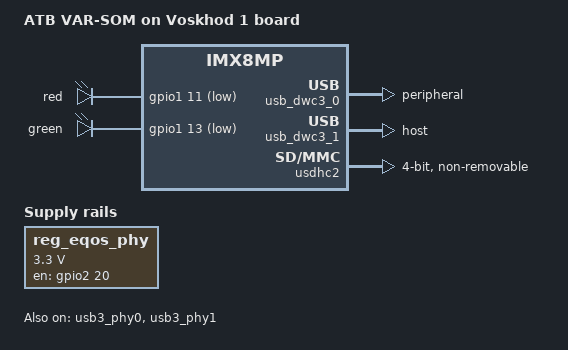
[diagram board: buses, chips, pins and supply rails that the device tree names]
// SPDX-License-Identifier: (GPL-2.0+ OR MIT)
/*
 * Copyright 2019 NXP
 * Copyright 2022 ATB
 */

/dts-v1/;

#include "imx8mp-var-som.dtsi"

/ {
	model = "ATB VAR-SOM on Voskhod 1 board";

	chosen {
		bootargs = "console=ttymxc1,115200 earlycon=ec_imx6q,0x30890000,115200";
		stdout-path = &uart2;
	};
	
	// TODO: Check
	leds {
		compatible = "gpio-leds";
		pinctrl-names = "default";
		pinctrl-0 = <&pinctrl_gpio_led>;

		red {
			label = "red";
			gpios = <&gpio1 11 GPIO_ACTIVE_LOW>;
			linux,default-trigger = "red";
			default-state = "off";
		};

		green {
			label = "green";
			gpios = <&gpio1 13 GPIO_ACTIVE_LOW>;
			linux,default-trigger = "green";
			default-state = "off";
		};
	};
	
	reg_eqos_phy: regulator-eqos-phy {
		compatible = "regulator-fixed";
		regulator-name = "eqos-phy";
		regulator-min-microvolt = <3300000>;
		regulator-max-microvolt = <3300000>;
		gpio = <&gpio2 20 GPIO_ACTIVE_HIGH>;
		enable-active-high;
		regulator-always-on;
	};
};

// TODO: Check
&usb3_phy0 {
	status = "okay";
};
// TODO: Check
&usb_dwc3_0 {
	dr_mode = "peripheral";
//	dr_mode = "otg";
	hnp-disable;
	srp-disable;
	adp-disable;
	usb-role-switch;
	status = "okay";
};
// TODO: Check
&usb3_phy1 {
	status = "okay";
};
// TODO: Check
&usb_dwc3_1 {
	dr_mode = "host";
	status = "okay";
};

// TODO: Check
&usdhc2 {
	pinctrl-names = "default", "state_100mhz", "state_200mhz";
	pinctrl-0 = <&pinctrl_usdhc2>, <&pinctrl_usdhc2_gpio>;
	pinctrl-1 = <&pinctrl_usdhc2_100mhz>, <&pinctrl_usdhc2_gpio>;
	pinctrl-2 = <&pinctrl_usdhc2_200mhz>, <&pinctrl_usdhc2_gpio>;
	// Card detect pin is temporarely unavailable.
	// Non removble mode is used.
//	cd-gpios = <&gpio1 14 GPIO_ACTIVE_LOW>;
	non-removable;
	bus-width = <4>;
	status = "okay";
};

&iomuxc {
	pinctrl_gpio_led: gpioledgrp {
		fsl,pins = <
			MX8MP_IOMUXC_NAND_READY_B__GPIO3_IO16	0x19
			MX8MP_IOMUXC_NAND_WE_B__GPIO3_IO17	0x19
		>;
	};

	pinctrl_usdhc2: usdhc2grp {
		fsl,pins = <
			MX8MP_IOMUXC_SD2_CLK__USDHC2_CLK				0x190
			MX8MP_IOMUXC_SD2_CMD__USDHC2_CMD				0x1d0
			MX8MP_IOMUXC_SD2_DATA0__USDHC2_DATA0				0x1d0
			MX8MP_IOMUXC_SD2_DATA1__USDHC2_DATA1				0x1d0
			MX8MP_IOMUXC_SD2_DATA2__USDHC2_DATA2				0x1d0
			MX8MP_IOMUXC_SD2_DATA3__USDHC2_DATA3				0x1d0
		>;
	};

	pinctrl_usdhc2_100mhz: usdhc2-100mhzgrp {
		fsl,pins = <
			MX8MP_IOMUXC_SD2_CLK__USDHC2_CLK				0x194
			MX8MP_IOMUXC_SD2_CMD__USDHC2_CMD				0x1d4
			MX8MP_IOMUXC_SD2_DATA0__USDHC2_DATA0				0x1d4
			MX8MP_IOMUXC_SD2_DATA1__USDHC2_DATA1				0x1d4
			MX8MP_IOMUXC_SD2_DATA2__USDHC2_DATA2				0x1d4
			MX8MP_IOMUXC_SD2_DATA3__USDHC2_DATA3				0x1d4
		>;
	};

	pinctrl_usdhc2_200mhz: usdhc2-200mhzgrp {
		fsl,pins = <
			MX8MP_IOMUXC_SD2_CLK__USDHC2_CLK				0x196
			MX8MP_IOMUXC_SD2_CMD__USDHC2_CMD				0x1d6
			MX8MP_IOMUXC_SD2_DATA0__USDHC2_DATA0				0x1d6
			MX8MP_IOMUXC_SD2_DATA1__USDHC2_DATA1				0x1d6
			MX8MP_IOMUXC_SD2_DATA2__USDHC2_DATA2				0x1d6
			MX8MP_IOMUXC_SD2_DATA3__USDHC2_DATA3				0x1d6
		>;
	};

	pinctrl_usdhc2_gpio: usdhc2-gpiogrp {
		fsl,pins = <
			MX8MP_IOMUXC_GPIO1_IO14__GPIO1_IO14				0x1c4
		>;
	};
};
